# ECM3531 register map
Vendor: EtaCompute; Series: ECM35xx; File version: 1.0.0
CPU: CM3 r1p1, little endian, MPU, no FPU, 3 interrupt priority bits
Registers are 32-bit, read-write, reset 0x0 unless marked. A register's access mark holds for its fields unless they carry their own. Offsets are from the block's base; [hi:lo] are bit positions; {n}, {i} and the like mark numbered series.

## SPI0 — SPI System Control Block Registers.
Base 0x50020000
Same registers: SPI1 0x50020100
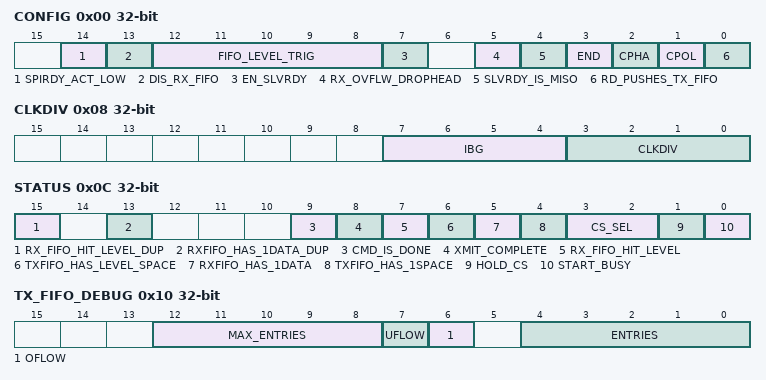
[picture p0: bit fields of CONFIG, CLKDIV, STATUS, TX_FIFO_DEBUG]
0x00 CONFIG — SPI configuration register.
  [14] SPIRDY_ACT_LOW — If 1, SPI Ready (from SPI_RDY or MISO) will be treated as active low (e.g. if 0, then we are ready and no flow control active). If 0 it is active high.
  [13] DIS_RX_FIFO — If 1, RX FIFO is disabled and will not receive any further data.
  [12:8] FIFO_LEVEL_TRIG — Program to the level that you want RX_FIFO_HIT_LEVEL to be set. If this reg is 2, then RX_FIFO_HIT_LEVEL will be set if the number of entries in RX_FIFO are 2 or greater.
  [7] EN_SLVRDY — If 1, SPI_RDY going low can stall the SPI transfers until it goes back high. Takes effect at byte boundaries. Note SLVRDY_IS_MISO can change if SPI_RDY or SPI_MISO is used as flow control.
  [5] RX_OVFLW_DROPHEAD — If 0, if the RX FIFO has an overflow, the first entries it received will be preserved. If 1, the most recent entries will be preserved. Note if 1, the RX_FIFO Overflow sticky bit will never bet set
  [4] SLVRDY_IS_MISO — If EN_SLVRDY is 0, this has no effect. If SLVRDY_IS_MISO is 0, then the RDY signal comes from SPI_RDY. If low, it comes from MISO. Note MISO data is not very helpful in this mode, but is not automatically disabled. Use RXDROP_CNT to drop RX data if needed.
  [3] END — If 0, transmit msbit first. If 1 send lsbit first.
  [2] CPHA — If 1, drive on PE (NE on CPOL=0) and sample on NE. If 0, drive on NE and sample on PE.
  [1] CPOL — CPOL indicates idle clock steady state
  [0] RD_PUSHES_TX_FIFO — If set to 1, the TX FIFO will empty as normal, but for every read pop that occurs, a new TX will be pushed into the FIFO. This is good for DMA.
0x04 TXRX_1BYTE_FIFO_DATA — SPI read and write data register.
  [7:0] DATA — Reads return receive data from SPI. Writes send data to transmit of SPI.
0x08 CLKDIV — SPI clock divider register.
  [7:4] IBG — The delay bewteen each byte will be (IBG+1) * CLKIN period (125ns).
  [3:0] CLKDIV — Controls SPI clock rate. SPI_CLK freq is PeriphClk / (CLKDIV+1). Min legal value is 1. Values 3 and above operate normally. Value 2 (2.6MHz) requires CONFIG2.RX_SAMPLE_TIME = 1 to operate. Value 1 (4MHz) requires CONFIG2.RX_SAMPLE_TIME = 2 and CONFIG2.DISABLE_MISO_METAFLOP = 1 to operate.
0x0C STATUS — SPI status register. Note that ANDing this register with INT_EN will effectively give you the unmasked interrupts.
  [15] RX_FIFO_HIT_LEVEL_DUP ro — This is a duplicate of STATUS.RX_FIFO_HIT_LEVEL presented here for interrupt simplicity.
  [13] RXFIFO_HAS_1DATA_DUP ro — This is a duplicate of STATUS.RXFIFO_HAS_1DATA presented here for interrupt simplicity.
  [9] CMD_IS_DONE ro — This is practically the inverse of STATUS.BUSY_DONE, but is presented here for regulatority in the interrupts.
  [8] XMIT_COMPLETE ro — If 1, all current transmits in TX_FIFO are complete and on the wire. Note that just because the transmits are complete, the command is not yet completed. If STATUS.HOLD_CS is set, the cmd will never complete until that bit is cleared. If that bit is cleared, the CS still needs to be deasserted. Look at STATUS.START_BUSY to determine if the command is done.
  [7] RX_FIFO_HIT_LEVEL ro — If 1, then there is at least CONFIG.FIFO_LEVEL_TRIG Byte(s) of data waiting in RX FIFO. Read TXRX_2BYTE_FIFO_DATA or RX_4BYTE_FIFO_DATA to get data.
  [6] TXFIFO_HAS_LEVEL_SPACE ro — If 1, then there is space to put If 1, then there is at least CONFIG.FIFO_LEVEL_TRIG Byte(s) of space available on TX_FIFO. If 0, there isn't.
  [5] RXFIFO_HAS_1DATA ro — If 1, then there is data waiting in RX FIFO. Read TXRX_1BYTE_FIFO_DATA to get data.
  [4] TXFIFO_HAS_1SPACE ro — If 1, then there is space to put onto the TX FIFO queue by writing to TXRX_1BYTE_FIFO_DATA. If 0, there isn't.
  [3:2] CS_SEL — Select which of the 4 chip selects to be used. 0=CS0, 1=CS1, 2=CS2 and 3=CS3. Note this bit is latched when start is written and is ignored until the next start.
  [1] HOLD_CS — If 1, CS stays active until this bit is cleared. If 0 the CS will go inactive after all data in TX FIFO has been transmitted.
  [0] START_BUSY — Write to 1 to start transaction. Read back to determine if the SM is START_BUSY (1) or if has gone back to idle (0). Note that a command can be finished but data is in the FIFOs.
0x10 TX_FIFO_DEBUG — SPI tx fifo debug register
  [12:8] MAX_ENTRIES ro — Max number of entries in FIFO.
  [7] UFLOW ro — Set when TX FIFO underflows. Cleared by setting CONFIG2.CLR_STICKY
  [6] OFLOW ro — Set when TX FIFO overflows. Newest entries are dropped. Cleared by setting CONFIG2.CLR_STICKY
  [4:0] ENTRIES ro — Entries in FIFO.
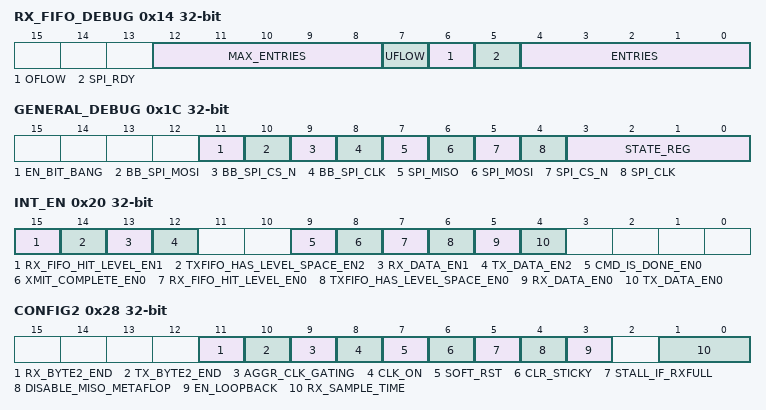
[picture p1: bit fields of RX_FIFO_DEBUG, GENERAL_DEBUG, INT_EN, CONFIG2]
0x14 RX_FIFO_DEBUG — SPI rx fifo debug register
  [12:8] MAX_ENTRIES ro — Max number of entries in FIFO.
  [7] UFLOW ro — Set when TX FIFO underflows. Cleared by setting CONFIG2.CLR_STICKY
  [6] OFLOW ro — Set when TX FIFO overflows. See CONFIG.RX_OVFLW_KEEPHEAD for details on drop behavior. Cleared by setting CONFIG2.CLR_STICKY
  [5] SPI_RDY ro — Live value of SPI_RDY
  [4:0] ENTRIES ro — Entries in FIFO.
0x18 RXDROP_CNT — RX Drop Byte Count
  [15:0] COUNT — Indicates how many RX bytes to silently drop before triggering an interrupt or rxfifo_has_data. Note, this should be written before the command begins to avoid cornercase issues.
0x1C GENERAL_DEBUG — SPI General Debug Fields
  [11] EN_BIT_BANG — If set, the BB_SPI_MOSI, BB_SPI_CS_N and BB_SPI_CLK control the SPI interface. The internal SM has no effect and can be placed in SOFT_RESET. However, the CONFIG2.CLK_ON bit should be set, or else the clock may gate off due to apparent quiescence.
  [10] BB_SPI_MOSI — Value to drive on of SPI_MOSI
  [9] BB_SPI_CS_N — Value to drive on SPI_CS_N
  [8] BB_SPI_CLK — Value to drive on SPI_CLK
  [7] SPI_MISO ro — Current value of SPI_MISO input
  [6] SPI_MOSI ro — Current value of SPI_MOSI
  [5] SPI_CS_N ro — Current value of SPI_CS_N
  [4] SPI_CLK ro — Current value of SPI_CLK
  [3:0] STATE_REG ro — Current state of primary State Machine
0x20 INT_EN — SPI Interrupt Enable Registger. Note that ANDing this register with STATUS will effectively give you the unmasked interrupts.
  [15] RX_FIFO_HIT_LEVEL_EN1 — If set to 1, the STATUS field RX_FIFO_HIT_LEVEL will be accelerated into an interrupt for spi_int1. Reading from TXRX_2BYTE_FIFO_DATA will force the interrupt to go low for at least one cycle, perhaps more if the RX FIFO is now empty.
  [14] TXFIFO_HAS_LEVEL_SPACE_EN2 — If set to 1, the STATUS field TXFIFO_HAS_LEVEL_SPACE will be accelerated into an interrupt for spi_int2. Writing to TXRX_2BYTE_FIFO_DATA will force the interrupt to go low for at least one cycle, perhaps more if the TX FIFO fills.
  [13] RX_DATA_EN1 — If set to 1, the STATUS field RXFIFO_HAS_DATA will be accelerated into an interrupt for spi_int1. Reading from TXRX_1BYTE_FIFO_DATA will force the interrupt to go low for at least one cycle, perhaps more if the RX FIFO is now empty.
  [12] TX_DATA_EN2 — If set to 1, the STATUS field TXFIFO_HAS_SPACE will be accelerated into an interrupt for spi_int2. Writing to TXRX_1BYTE_FIFO_DATA will cause this to go low for at least one cycle, perhaps more if the TX FIFO fills.
  [9] CMD_IS_DONE_EN0 — The spi_int0 will fire when the all data in TX_FIFO and dummy bytes have been transmitted. Note that STATUS.HOLD_CS must be high this interrupt to be set.
  [8] XMIT_COMPLETE_EN0 — The spi_int0 will fire when the all data in TX_FIFO and dummy bytes have been transmitted. Note that STATUS.HOLD_CS must be high this interrupt to be set.
  [7] RX_FIFO_HIT_LEVEL_EN0 — If set to 1, the STATUS field RX_FIFO_HIT_LEVEL will be accelerated into an interrupt for spi_int0. Reading from TXRX_1BYTE_FIFO_DATA will force the interrupt to go low for at least one cycle, perhaps more if the RX FIFO is now empty.
  [6] TXFIFO_HAS_LEVEL_SPACE_EN0 — If set to 1, the STATUS field TXFIFO_HAS_LEVEL_SPACE will be accelerated into an interrupt for spi_int0. Writing to TXRX_2BYTE_FIFO_DATA will force the interrupt to go low for at least one cycle, perhaps more if the TX FIFO fills.
  [5] RX_DATA_EN0 — If set to 1, the STATUS field RXFIFO_HAS_DATA will be accelerated into an interrupt for spi_int0. Reading from TXRX_1BYTE_FIFO_DATA will force the interrupt to go low for at least one cycle, perhaps more if the RX FIFO is now empty.
  [4] TX_DATA_EN0 — If set to 1, the STATUS field TXFIFO_HAS_SPACE will be accelerated into an interrupt for spi_int0. Writing to TXRX_1BYTE_FIFO_DATA will cause this to go low for at least one cycle, perhaps more if the TX FIFO fills.
0x24 TXRX_2BYTE_FIFO_DATA — SPI read and write data register.
  [15:0] DATA — 2 byte reads return receive data from SPI. 2 byte writes send data to transmit of SPI. By default, data is presented in little endian so bit [7:0] will have the first byte that was received or to be transmitted, bit [15:8] will have the second byte received or to be transmitted. By setting CONFIG2.TX_BYTE2_END or CONFIG2.RX_BYTE2_END, this order can be reversed.
0x28 CONFIG2 — SPI configuration2 register.
  [11] RX_BYTE2_END — Only used for 16 or 32 bit transfers. If 0, then the first byte received on MISO is in position data[7:0], the second is data[15:8]. Similarly, if 0, then 4 byte read will have the first byte received in position data[7:0], the next byte in [15:8], etc. If 1, vice versa and first byte is in position [15:8] for 2 byte read and [31:24] in 4 byte read. This affects only RX side
  [10] TX_BYTE2_END — Only used for 16 or 32 bit transfers. If 0, data[7:0] is transmitted on MOSI before data[15:8]. If 1, vice versa. This affects only TX side
  [9] AGGR_CLK_GATING — If set to 1, a more aggressive clock gating scheme is enacted that will clock the gate even if the command is still in flight, but the FIFOs, etc. have emptied (i.e. processor has starved FIFOs). If 0, we only gate when the command is complete.
  [8] CLK_ON — This bit provides an override to the clock gate enable. If 0, the clock will only run if the local state machine is busy. If 1, the clock will always run.
  [7] SOFT_RST — If 1, all FIFO / SM in SPI will be held in reset. If 0, normal operation. To do a soft reset, you must write this to 1 and then back to 0 to remove the reset.
  [6] CLR_STICKY — If 1, clear sticky bits in registers. If 0, normal operation. To do a soft reset, you must write this to 1 and then back to 0 to remove the reset.
  [5] STALL_IF_RXFULL — If 1, the TX side will stall if RX FIFO is full.
  [4] DISABLE_MISO_METAFLOP — 0 is the normal, recommended flow. If 1, the 2 CLKIN delay of MISO is bypassed allowing for faster operation at the risk of metastablity if MISO changes near sample time. Normally MISO should change with >100 ns setup / hold, so it may be a viable risk.
  [3] EN_LOOPBACK — 0 is the normal flow. If 1, MISO comes directly from MOSI. Note that CSN and SPI_CLK are outputs and are effectively ignored in loopback mode.
  [1:0] RX_SAMPLE_TIME — Used to adjust receive ssample time. Can be modified to increase max speed at cost of setup, metastability flops. Normal flow uses 2 delay FF of early signal. (i.e. delay[1]. 00=delay[1], 01=delay[0], 10=early, 11=delay[2]
0x2C TX_DUMMY_BYTE_CNT — spi transmit dummy byte count
  [15:0] COUNT — Every write to this register increements the DUMMY_BYTE_COUNT by the bits written. The DUMMY bytes are added to the tail of the TX FIFO, thus allowing for a large number of dummy bytes (e.g. to allow for receive operations) to put fed into the TX FIFO. The counter can hold 16 bits worth (64K-1). A read of this field and concatenated with COUNT_UPPER will indicate teh current dummy byte count. Note that the upper byte must be written even if it is written with a zero. That write of the upper byte triggers the counter to start. Note that since every SPI RX entry requires one SPI TX entry, setting the Dummy Byte Count effectively gives us the length of the transaction. Note that the CS_HOLD bit can be cleared and the logic will keep the FIFO filled until Dummy Bytes have been exhausted. Note once any dummy bytes are written, the user should not write to the TX FIFO again as this will cause interspersed dummy bytes (0x00) and newly written data on the SPI MOSI line. The max value allowed in the DUMMY_BYTE counter is 0xffff (64K-1)
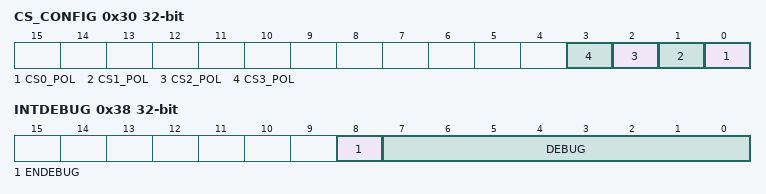
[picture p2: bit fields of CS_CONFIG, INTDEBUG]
0x30 CS_CONFIG — SPI Chip select config
  [n] CS{n}_POL (n=0..3) — If 0, the CS is active low and will default to 1 until the device is selected and then drive to a 0. If 1, it is reversed (active high)
0x34 RX_4BYTE_FIFO_DATA — SPI read data register. Note this register is disabled in DSP instances.
  [31:0] DATA — 4 byte reads return receive data from SPI. Writes have no effect. By default, data is returned little endian so bit [7:0] will have the first byte that was received, bit [15:8] will have the second byte received, etc. up to bit [31:24] having the fourth byte received. By setting CONFIG2.RX_BYTE2_END, this order can be reversed.
0x38 INTDEBUG — Internal debug. Note this register is only enabled in DSP instances.
  [8] ENDEBUG — Write to 1 to enable debug.
  [7:0] DEBUG — Debug. Reads return intdbg state. When 0, it is idle. Write to begin debug.
